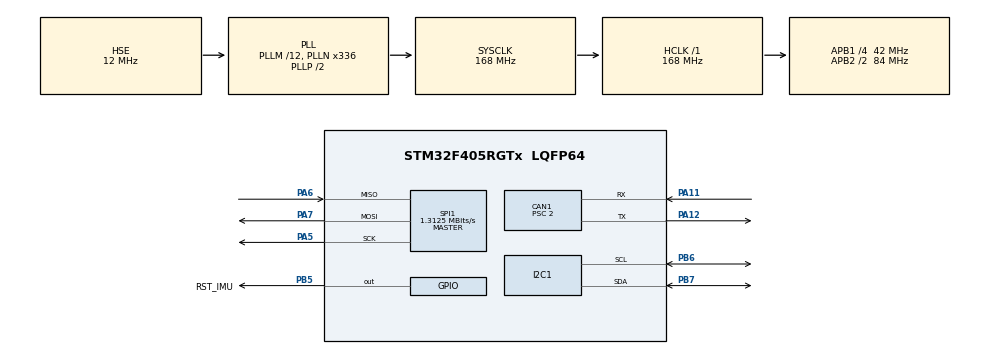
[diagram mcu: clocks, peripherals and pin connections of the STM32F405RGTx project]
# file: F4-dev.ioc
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CAN1.ABOM=DISABLE
CAN1.AWUM=DISABLE
CAN1.BS1=CAN_BS1_14TQ
CAN1.BS2=CAN_BS2_6TQ
CAN1.CalculateTimeQuantum=47.61904761904762
CAN1.Prescaler=2
FREERTOS.CountingSemaphores01=myCountingSem01,1,Dynamic,NULL
FREERTOS.INCLUDE_pcTaskGetTaskName=1
FREERTOS.INCLUDE_xEventGroupSetBitFromISR=1
FREERTOS.INCLUDE_xSemaphoreGetMutexHolder=1
FREERTOS.INCLUDE_xTaskGetCurrentTaskHandle=1
FREERTOS.Tasks01=defaultTask,24,128,StartDefaultTask,Default,NULL,Dynamic,NULL,NULL
FREERTOS.configENABLE_FPU=1
FREERTOS.configTICK_RATE_HZ=400
FREERTOS.configUSE_APPLICATION_TASK_TAG=1
I2C1.I2C_Mode=I2C_Fast
Mcu.Family=STM32F4
Mcu.Name=STM32F405RGTx
Mcu.Package=LQFP64
NVIC.CAN1_RX0_IRQn=true\:5\:0\:false\:false\:true\:true\:true\:true
NVIC.PriorityGroup=NVIC_PRIORITYGROUP_4
NVIC.TIM4_IRQn=true\:0\:0\:false\:false\:true\:false\:false\:true
NVIC.TimeBase=TIM4_IRQn
NVIC.TimeBaseIP=TIM4
PA11.Mode=Master
PA11.Signal=CAN1_RX
PA12.Mode=Master
PA12.Signal=CAN1_TX
PA13.Mode=Serial_Wire
PA13.Signal=SYS_JTMS-SWDIO
PA14.Mode=Serial_Wire
PA14.Signal=SYS_JTCK-SWCLK
PA5.Mode=Full_Duplex_Master
PA5.Signal=SPI1_SCK
PA6.Mode=Full_Duplex_Master
PA6.Signal=SPI1_MISO
PA7.Mode=Full_Duplex_Master
PA7.Signal=SPI1_MOSI
PB13.Signal=SPI2_SCK
PB5.GPIO_Label=RST_IMU
PB5.GPIO_PuPd=GPIO_PULLUP
PB5.PinState=GPIO_PIN_SET
PB5.Signal=GPIO_Output
PB6.Mode=I2C
PB6.Signal=I2C1_SCL
PB7.Mode=I2C
PB7.Signal=I2C1_SDA
PH0-OSC_IN.Mode=HSE-External-Oscillator
PH0-OSC_IN.Signal=RCC_OSC_IN
PH1-OSC_OUT.Mode=HSE-External-Oscillator
PH1-OSC_OUT.Signal=RCC_OSC_OUT
ProjectManager.HeapSize=0x1000
ProjectManager.StackSize=0x2000
ProjectManager.TargetToolchain=MDK-ARM V5
RCC.48MHZClocksFreq_Value=42000000
RCC.AHBFreq_Value=168000000
RCC.APB1CLKDivider=RCC_HCLK_DIV4
RCC.APB1Freq_Value=42000000
RCC.APB1TimFreq_Value=84000000
RCC.APB2CLKDivider=RCC_HCLK_DIV2
RCC.APB2Freq_Value=84000000
RCC.APB2TimFreq_Value=168000000
RCC.CortexFreq_Value=168000000
RCC.HCLKFreq_Value=168000000
RCC.HSE_VALUE=12000000
RCC.HSI_VALUE=16000000
RCC.LSE_VALUE=32768
RCC.PLLM=12
RCC.PLLN=336
RCC.PLLQ=8
RCC.PLLSourceVirtual=RCC_PLLSOURCE_HSE
RCC.SYSCLKFreq_VALUE=168000000
RCC.SYSCLKSource=RCC_SYSCLKSOURCE_PLLCLK
RCC.VCOOutputFreq_Value=336000000
SPI1.BaudRatePrescaler=SPI_BAUDRATEPRESCALER_64
SPI1.CLKPhase=SPI_PHASE_2EDGE
SPI1.CLKPolarity=SPI_POLARITY_HIGH
SPI1.CalculateBaudRate=1.3125 MBits/s
SPI1.DataSize=SPI_DATASIZE_16BIT
SPI1.Direction=SPI_DIRECTION_2LINES
SPI1.Mode=SPI_MODE_MASTER
SPI1.VirtualType=VM_MASTER
VP_FREERTOS_VS_CMSIS_V2.Mode=CMSIS_V2
VP_SYS_VS_tim4.Mode=TIM4
board=custom

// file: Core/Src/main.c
/* USER CODE BEGIN Header */
/**
  ******************************************************************************
  * @file           : main.c
  * @brief          : Main program body
  ******************************************************************************
  * @attention
  *
  * <h2><center>&copy; Copyright (c) 2020 STMicroelectronics.
  * All rights reserved.</center></h2>
  *
  * This software component is licensed by ST under Ultimate Liberty license
  * SLA0044, the "License"; You may not use this file except in compliance with
  * the License. You may obtain a copy of the License at:
  *                             www.st.com/SLA0044
  *
  ******************************************************************************
  */
/* USER CODE END Header */

#include "main.h"
#include "cmsis_os.h"
#include "can.h"
#include "i2c.h"
#include "spi.h"
#include "gpio.h"

/* USER CODE BEGIN PV */
uint32_t rcc_clock=0;
/* USER CODE END PV */

void SystemClock_Config(void);
void MX_FREERTOS_Init(void);

int main(void)
{

  /* MCU Configuration--------------------------------------------------------*/

  /* Reset of all peripherals, Initializes the Flash interface and the Systick. */
  HAL_Init();

  /* Configure the system clock */
  SystemClock_Config();

  /* Initialize all configured peripherals */
  MX_GPIO_Init();
  MX_CAN1_Init();
  MX_I2C1_Init();
  MX_SPI1_Init();
  /* USER CODE BEGIN 2 */
  rcc_clock = HAL_RCC_GetSysClockFreq();
  /* USER CODE END 2 */

  /* Init scheduler */
  osKernelInitialize();  /* Call init function for freertos objects (in freertos.c) */
  MX_FREERTOS_Init();
  /* Start scheduler */
  osKernelStart();

  /* We should never get here as control is now taken by the scheduler */
  /* Infinite loop */
  while (1)
  {

  }
}

void SystemClock_Config(void)
{
  RCC_OscInitTypeDef RCC_OscInitStruct = {0};
  RCC_ClkInitTypeDef RCC_ClkInitStruct = {0};

  /** Configure the main internal regulator output voltage
  */
  __HAL_RCC_PWR_CLK_ENABLE();
  __HAL_PWR_VOLTAGESCALING_CONFIG(PWR_REGULATOR_VOLTAGE_SCALE1);
  /** Initializes the CPU, AHB and APB busses clocks
  */
  RCC_OscInitStruct.OscillatorType = RCC_OSCILLATORTYPE_HSE;
  RCC_OscInitStruct.HSEState = RCC_HSE_ON;
  RCC_OscInitStruct.PLL.PLLState = RCC_PLL_ON;
  RCC_OscInitStruct.PLL.PLLSource = RCC_PLLSOURCE_HSE;
  RCC_OscInitStruct.PLL.PLLM = 12;
  RCC_OscInitStruct.PLL.PLLN = 336;
  RCC_OscInitStruct.PLL.PLLP = RCC_PLLP_DIV2;
  RCC_OscInitStruct.PLL.PLLQ = 8;
  if (HAL_RCC_OscConfig(&RCC_OscInitStruct) != HAL_OK)
  {
    Error_Handler();
  }
  /** Initializes the CPU, AHB and APB busses clocks
  */
  RCC_ClkInitStruct.ClockType = RCC_CLOCKTYPE_HCLK|RCC_CLOCKTYPE_SYSCLK
                              |RCC_CLOCKTYPE_PCLK1|RCC_CLOCKTYPE_PCLK2;
  RCC_ClkInitStruct.SYSCLKSource = RCC_SYSCLKSOURCE_PLLCLK;
  RCC_ClkInitStruct.AHBCLKDivider = RCC_SYSCLK_DIV1;
  RCC_ClkInitStruct.APB1CLKDivider = RCC_HCLK_DIV4;
  RCC_ClkInitStruct.APB2CLKDivider = RCC_HCLK_DIV2;

  if (HAL_RCC_ClockConfig(&RCC_ClkInitStruct, FLASH_LATENCY_5) != HAL_OK)
  {
    Error_Handler();
  }
}

 /**
  * @brief  Period elapsed callback in non blocking mode
  * @note   This function is called  when TIM4 interrupt took place, inside
  * HAL_TIM_IRQHandler(). It makes a direct call to HAL_IncTick() to increment
  * a global variable "uwTick" used as application time base.
  * @param  htim : TIM handle
  * @retval None
  */
void HAL_TIM_PeriodElapsedCallback(TIM_HandleTypeDef *htim)
{
  if (htim->Instance == TIM4) {
    HAL_IncTick();
  }
}

void Error_Handler(void)
{
}

/************************ (C) COPYRIGHT STMicroelectronics *****END OF FILE****/

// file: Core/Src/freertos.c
/* USER CODE BEGIN Header */
/**
  ******************************************************************************
  * File Name          : freertos.c
  * Description        : Code for freertos applications
  ******************************************************************************
  * @attention
  *
  * <h2><center>&copy; Copyright (c) 2020 STMicroelectronics.
  * All rights reserved.</center></h2>
  *
  * This software component is licensed by ST under Ultimate Liberty license
  * SLA0044, the "License"; You may not use this file except in compliance with
  * the License. You may obtain a copy of the License at:
  *                             www.st.com/SLA0044
  *
  ******************************************************************************
  */
/* USER CODE END Header */

#include "FreeRTOS.h"
#include "task.h"
#include "main.h"
#include "cmsis_os.h"

/* USER CODE BEGIN Includes */
#include "imu_drv.h"
#include "can.h"
/* USER CODE END Includes */

/* Definitions for defaultTask */
osThreadId_t defaultTaskHandle;
const osThreadAttr_t defaultTask_attributes = {
  .name = "defaultTask",
  .priority = (osPriority_t) osPriorityNormal,
  .stack_size = 128 * 4
};
/* Definitions for myCountingSem01 */
osSemaphoreId_t myCountingSem01Handle;
const osSemaphoreAttr_t myCountingSem01_attributes = {
  .name = "myCountingSem01"
};

void StartDefaultTask(void *argument);

void MX_FREERTOS_Init(void); /* (MISRA C 2004 rule 8.1) */

void MX_FREERTOS_Init(void) {

  /* Create the semaphores(s) */
  /* creation of myCountingSem01 */
  myCountingSem01Handle = osSemaphoreNew(1, 1, &myCountingSem01_attributes);

  /* Create the thread(s) */
  /* creation of defaultTask */
  defaultTaskHandle = osThreadNew(StartDefaultTask, NULL, &defaultTask_attributes);

}

void StartDefaultTask(void *argument)
{
  /* USER CODE BEGIN StartDefaultTask */

  // SPI_Master_Init_Normal();
  // SPI_Master_Init_Ext();
  I2C_Master_Init();
  // CAN_User_Init(&hcan1);
  /* Infinite loop */
  for(;;)
  {
    osDelay(4);

    // SPI_Master_Read_Normal();
    // SPI_Master_Read_Ext();
    I2C_Master_Read();
  }
  /* USER CODE END StartDefaultTask */
}

/************************ (C) COPYRIGHT STMicroelectronics *****END OF FILE****/
